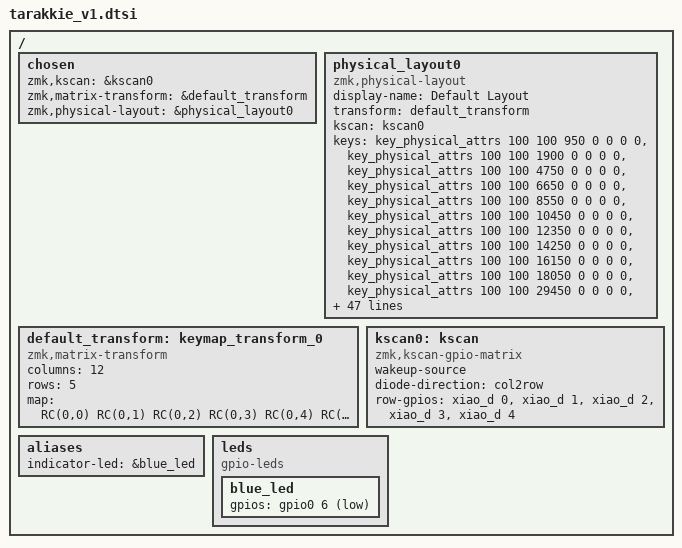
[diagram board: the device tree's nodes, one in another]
/*
 * Copyright (c) 2025 The ZMK Contributors
 *
 * SPDX-License-Identifier: MIT
 */

#include <dt-bindings/zmk/matrix_transform.h>
#include <physical_layouts.dtsi>

/ {
    chosen {
        zmk,kscan = &kscan0;
        zmk,matrix-transform = &default_transform;
        zmk,physical-layout = &physical_layout0;
    };



    physical_layout0: physical_layout0 {
        compatible = "zmk,physical-layout";
        display-name = "Default Layout";
        transform = <&default_transform>;
        kscan = <&kscan0>;
        keys  // 58 keys - w   h    x    y   rot  rx  ry
            = <&key_physical_attrs 100 100   950     0 0 0 0>
            , <&key_physical_attrs 100 100  1900     0 0 0 0>
            , <&key_physical_attrs 100 100  4750     0 0 0 0>
            , <&key_physical_attrs 100 100  6650     0 0 0 0>
            , <&key_physical_attrs 100 100  8550     0 0 0 0>
            , <&key_physical_attrs 100 100 10450     0 0 0 0>
            , <&key_physical_attrs 100 100 12350     0 0 0 0>
            , <&key_physical_attrs 100 100 14250     0 0 0 0>
            , <&key_physical_attrs 100 100 16150     0 0 0 0>
            , <&key_physical_attrs 100 100 18050     0 0 0 0>
            , <&key_physical_attrs 100 100 29450     0 0 0 0>
            , <&key_physical_attrs 100 100 31350     0 0 0 0>
            , <&key_physical_attrs 100 100   950  1425 0 0 0>
            , <&key_physical_attrs 100 100  1900  1425 0 0 0>
            , <&key_physical_attrs 100 100  4750  1425 0 0 0>
            , <&key_physical_attrs 100 100  6650  1425 0 0 0>
            , <&key_physical_attrs 100 100  8550  1425 0 0 0>
            , <&key_physical_attrs 100 100 10450  1425 0 0 0>
            , <&key_physical_attrs 100 100 12350  1425 0 0 0>
            , <&key_physical_attrs 100 100 14250  1425 0 0 0>
            , <&key_physical_attrs 100 100 16150  1425 0 0 0>
            , <&key_physical_attrs 100 100 18050  1425 0 0 0>
            , <&key_physical_attrs 100 100 29450  1425 0 0 0>
            , <&key_physical_attrs 100 100 31350  1425 0 0 0>
            , <&key_physical_attrs 100 100   950  2850 0 0 0>
            , <&key_physical_attrs 100 100  1900  2850 0 0 0>
            , <&key_physical_attrs 100 100  4750  2850 0 0 0>
            , <&key_physical_attrs 100 100  6650  2850 0 0 0>
            , <&key_physical_attrs 100 100  8550  2850 0 0 0>
            , <&key_physical_attrs 100 100 10450  2850 0 0 0>
            , <&key_physical_attrs 100 100 12350  2850 0 0 0>
            , <&key_physical_attrs 100 100 14250  2850 0 0 0>
            , <&key_physical_attrs 100 100 16150  2850 0 0 0>
            , <&key_physical_attrs 100 100 18050  2850 0 0 0>
            , <&key_physical_attrs 100 100 29450  2850 0 0 0>
            , <&key_physical_attrs 100 100 31350  2850 0 0 0>
            , <&key_physical_attrs 100 100   950  4275 0 0 0>
            , <&key_physical_attrs 100 100  1900  4275 0 0 0>
            , <&key_physical_attrs 100 100  4750  4275 0 0 0>
            , <&key_physical_attrs 100 100  6650  4275 0 0 0>
            , <&key_physical_attrs 100 100  8550  4275 0 0 0>
            , <&key_physical_attrs 100 100 10450  4275 0 0 0>
            , <&key_physical_attrs 100 100 11400  4275 0 0 0>
            , <&key_physical_attrs 100 100 13300  4275 0 0 0>
            , <&key_physical_attrs 100 100 14250  4275 0 0 0>
            , <&key_physical_attrs 100 100 16150  4275 0 0 0>
            , <&key_physical_attrs 100 100 18050  4275 0 0 0>
            , <&key_physical_attrs 100 100 29450  4275 0 0 0>
            , <&key_physical_attrs 100 100 31350  4275 0 0 0>
            , <&key_physical_attrs 100 100 12350  4275 0 0 0>
            , <&key_physical_attrs 100 100  5415  5225 0 0 0>
            , <&key_physical_attrs 100 100  7315  5225 0 0 0>
            , <&key_physical_attrs 100 100 11117  5225 0 0 0>
            , <&key_physical_attrs 100 100 14535  5225 0 0 0>
            , <&key_physical_attrs 100 100 18468  5225 0 0 0>
            , <&key_physical_attrs 100 100 23275  5225 0 0 0>
            , <&key_physical_attrs 100 100 27835  5700 0 0 0>
            , <&key_physical_attrs 100 100 29735  5700 0 0 0>
            ;
    };

    default_transform: keymap_transform_0 {
        compatible = "zmk,matrix-transform";
        columns = <12>;
        rows = <5>;
        // | SW1  | SW2  | SW3  | SW4  | SW5  | SW6  |                 | SW6  | SW5  | SW4  | SW3  | SW2  | SW1  |
        // | SW7  | SW8  | SW9  | SW10 | SW11 | SW12 |                 | SW12 | SW11 | SW10 | SW9  | SW8  | SW7  |
        // | SW13 | SW14 | SW15 | SW16 | SW17 | SW18 |                 | SW18 | SW17 | SW16 | SW15 | SW14 | SW13 |
        // | SW19 | SW20 | SW21 | SW22 | SW23 | SW24 | SW25 |   | SW25 | SW24 | SW23 | SW22 | SW21 | SW20 | SW19 |
        //                      | SW26 | SW27 | SW28 | SW29 |   | SW29 | SW28 | SW27 | SW26 |
        map = <
RC(0,0) RC(0,1) RC(0,2) RC(0,3) RC(0,4) RC(0,5)                 RC(0,6) RC(0,7) RC(0,8) RC(0,9) RC(0,10) RC(0,11)
RC(1,0) RC(1,1) RC(1,2) RC(1,3) RC(1,4) RC(1,5)                 RC(1,6) RC(1,7) RC(1,8) RC(1,9) RC(1,10) RC(1,11)
RC(2,0) RC(2,1) RC(2,2) RC(2,3) RC(2,4) RC(2,5)                 RC(2,6) RC(2,7) RC(2,8) RC(2,9) RC(2,10) RC(2,11)
RC(3,0) RC(3,1) RC(3,2) RC(3,3) RC(3,4) RC(3,5) RC(4,5) RC(4,6) RC(3,6) RC(3,7) RC(3,8) RC(3,9) RC(3,10) RC(3,11)
                        RC(4,0) RC(4,1) RC(4,2) RC(4,3) RC(4,7) RC(4,8) RC(4,9) RC(4,10)
        >;
    };

    kscan0: kscan {
        compatible = "zmk,kscan-gpio-matrix";
        wakeup-source;

        diode-direction = "col2row";
        row-gpios
            = <&xiao_d 0 (GPIO_ACTIVE_HIGH | GPIO_PULL_DOWN)>
            , <&xiao_d 1 (GPIO_ACTIVE_HIGH | GPIO_PULL_DOWN)>
            , <&xiao_d 2 (GPIO_ACTIVE_HIGH | GPIO_PULL_DOWN)>
            , <&xiao_d 3 (GPIO_ACTIVE_HIGH | GPIO_PULL_DOWN)>
            , <&xiao_d 4 (GPIO_ACTIVE_HIGH | GPIO_PULL_DOWN)>
            ;
    };
};

/ {
    aliases {
        indicator-led = &blue_led;
    };

    leds {
        compatible = "gpio-leds";
        blue_led: blue_led {
            gpios = <&gpio0 6 GPIO_ACTIVE_LOW>;
        };
    };
};
